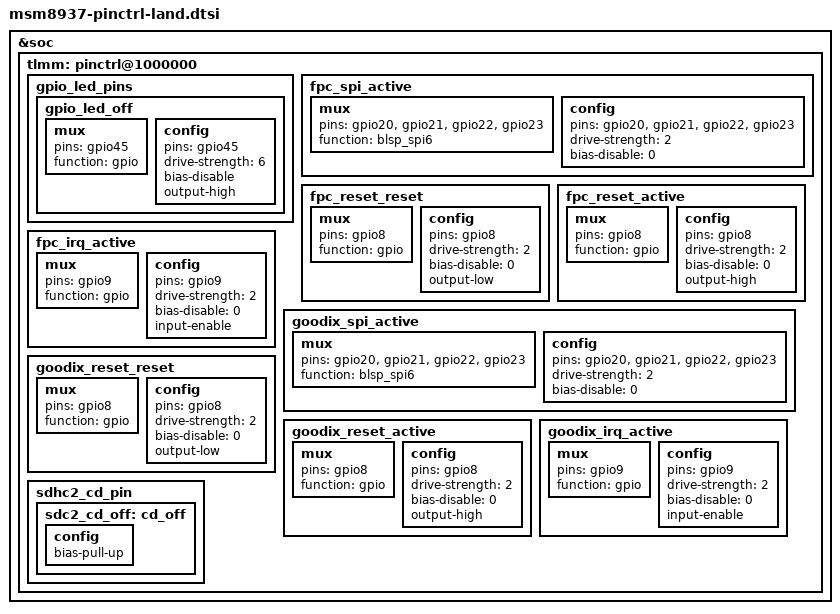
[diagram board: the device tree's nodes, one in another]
/*
 * Copyright (c) 2015-2016, The Linux Foundation. All rights reserved.
 *
 * This program is free software; you can redistribute it and/or modify
 * it under the terms of the GNU General Public License version 2 and
 * only version 2 as published by the Free Software Foundation.
 *
 * This program is distributed in the hope that it will be useful,
 * but WITHOUT ANY WARRANTY; without even the implied warranty of
 * MERCHANTABILITY or FITNESS FOR A PARTICULAR PURPOSE.  See the
 * GNU General Public License for more details.
 */

&soc {
       tlmm: pinctrl@1000000 {

		gpio_led_pins {
			gpio_led_off: gpio_led_off {
				mux {
					pins = "gpio45";
					function = "gpio";
				};
				config {
					pins = "gpio45";
					drive-strength = <6>;
					bias-disable;
					output-high;
				};
			};
		};

		fpc_spi_active: fpc_spi_active{
			mux {
				pins = "gpio20", "gpio21", "gpio22", "gpio23";
				function = "blsp_spi6";
			};
			config {
				pins = "gpio20", "gpio21", "gpio22", "gpio23";
				drive-strength = <2>;
				bias-disable = <0>;
			};
		};
		fpc_reset_reset: fpc_reset_reset{
			mux {
				pins = "gpio8";
				function = "gpio";
			};
			config {
				pins = "gpio8";
				drive-strength = <2>;
				bias-disable = <0>;
				output-low;
			};
		};
		fpc_reset_active: fpc_reset_active{
			mux {
				pins = "gpio8";
				function = "gpio";
			};
			config {
				pins = "gpio8";
				drive-strength = <2>;
				bias-disable = <0>;
				output-high;
			};
		};

		fpc_irq_active: fpc_irq_active {
			mux {
				pins = "gpio9";
				function = "gpio";
			};
			config {
				pins = "gpio9";
				drive-strength = <2>;
				bias-disable = <0>;
				input-enable;
			};
		};
		goodix_spi_active: goodix_spi_active{
			mux {
				pins = "gpio20", "gpio21", "gpio22", "gpio23";
				function = "blsp_spi6";
			};
			config {
				pins = "gpio20", "gpio21", "gpio22", "gpio23";
				drive-strength = <2>;
				bias-disable = <0>;
			};
		};
		goodix_reset_reset: goodix_reset_reset{
			mux {
				pins = "gpio8";
				function = "gpio";
			};
			config {
				pins = "gpio8";
				drive-strength = <2>;
				bias-disable = <0>;
				output-low;
			};
		};
		goodix_reset_active: goodix_reset_active{
			mux {
				pins = "gpio8";
				function = "gpio";
			};
			config {
				pins = "gpio8";
				drive-strength = <2>;
				bias-disable = <0>;
				output-high;
			};
		};

		goodix_irq_active: goodix_irq_active {
			mux {
				pins = "gpio9";
				function = "gpio";
			};
			config {
				pins = "gpio9";
				drive-strength = <2>;
				bias-disable = <0>;
				input-enable;
			};
		};
                sdhc2_cd_pin {
                        sdc2_cd_off: cd_off {
                                config {
                                       /delete-property/ bias-disable;
					bias-pull-up;
                                };
                        };
                };
    };
};
